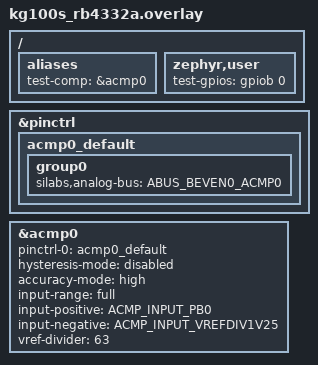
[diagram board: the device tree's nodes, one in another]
/*
 * Copyright (c) 2026 Martin Moya <martin.moya@focus.uy>
 *
 * SPDX-License-Identifier: Apache-2.0
 */

/*
 * Connect PB0 to itself — drive it as GPIO (test-gpios) and
 * measure it as ACMP input (ACMP_INPUT_PD1 via ABUS_CDODD0_ACMP0).
 */

#include <zephyr/dt-bindings/gpio/gpio.h>
#include <zephyr/dt-bindings/comparator/silabs-acmp.h>
#include <zephyr/dt-bindings/pinctrl/silabs/xg21-pinctrl.h>

/ {
	aliases {
		test-comp = &acmp0;
	};

	zephyr,user {
		test-gpios = <&gpiob 0 GPIO_ACTIVE_HIGH>;
	};
};

&pinctrl {
	acmp0_default: acmp0_default {
		group0 {
			silabs,analog-bus = <ABUS_BEVEN0_ACMP0>;
		};
	};
};

&acmp0 {
	pinctrl-0 = <&acmp0_default>;
	pinctrl-names = "default";
	status = "okay";

	hysteresis-mode = "disabled";
	accuracy-mode = "high";
	input-range = "full";
	input-positive = <ACMP_INPUT_PB0>;
	input-negative = <ACMP_INPUT_VREFDIV1V25>;
	vref-divider = <63>;
};
